# AT32F403A register map
Vendor: Keil; Series: AT32F403A; File version: 1.0
CPU: CM4 r0p1, little endian, no MPU, FPU, 4 interrupt priority bits
Registers are 32-bit, read-write, reset 0x0 unless marked. A register's access mark holds for its fields unless they carry their own. Offsets are from the block's base; [hi:lo] are bit positions; lines under a group give offsets from that group; {n}, {i} and the like mark numbered series.

## DMA1 — DMA controller
Base 0x40020000
Same registers: DMA2 0x40020400
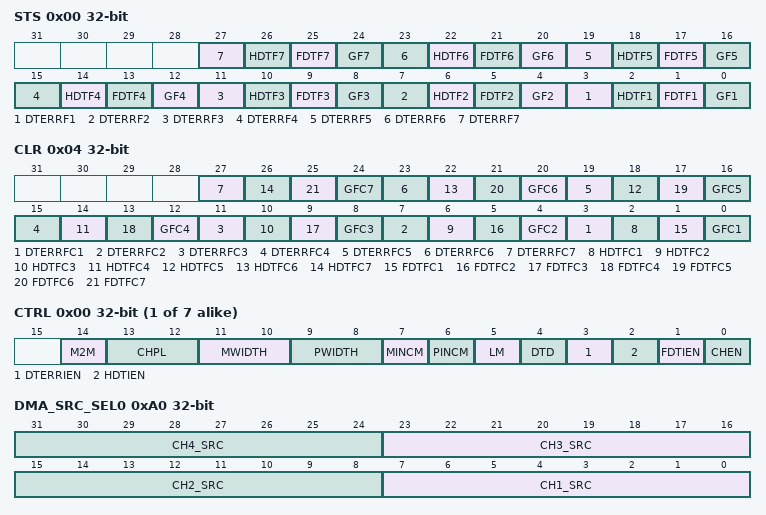
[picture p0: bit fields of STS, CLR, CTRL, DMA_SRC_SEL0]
0x00 STS ro — DMA interrupt status register (DMA_STS)
  [4n-1] DTERRF{n} (n=1..7) — Channel {n} data transfer error event flag
    0=NoTransferError; 1=TransferError (A transfer error occurred)
  [4n-2] HDTF{n} (n=1..7) — Channel {n} half transfer event flag
    0=NoHalfTransfer; 1=HalfTransfer (A half transfer occurred)
  [4n-3] FDTF{n} (n=1..7) — Channel {n} data transfer complete event flag
    0=NoTransferComplete; 1=TransferComplete (A transfer complete occurred)
  [4n-4] GF{n} (n=1..7) — Channel {n} global event flag
    0=NoEvent; 1=Event (An event occurred (transfer error, half transfer or transfer complete))
0x04 CLR — DMA interrupt flag clear register (DMA_CLR)
  [4n-1] DTERRFC{n} (n=1..7) write-1-clears — Channel {n} data transfer error flag clear
    1=Clear the transfer error flag
  [4n-2] HDTFC{n} (n=1..7) write-1-clears — Channel {n} half transfer flag clear
    1=Clear the half transfer flag
  [4n-3] FDTFC{n} (n=1..7) write-1-clears — Channel {n} data transfer complete flag clear
    1=Clear the transfer complete flag
  [4n-4] GFC{n} (n=1..7) write-1-clears — Channel {n} global flag clear
    1=Clear all flags DTERRFx, HDTFx, FDTFx and GFx
0x08 Channel{i} (i=1..7; step 0x14) group — DMA Channel {i}
  0x00 CTRL — DMA channel configuration register
    [14] M2M — Memory to memory mode
      on read: 0=Disabled (Memory to memory mode is disabled); 1=Enabled (Memory to memory mode is enabled) | on write: 0=Disable (Memory to memory mode disable); 1=Enable (Memory to memory mode enable)
    [13:12] CHPL — Channel Priority level
      0=Low; 1=Medium; 2=High; 3=VeryHigh
    [11:10] MWIDTH — Memory data bit width
      0=bit8 (8 bits); 1=bit16 (16 bits); 2=bit32 (32 bits)
    [9:8] PWIDTH — Peripheral data bit width
      0=bit8 (8 bits); 1=bit16 (16 bits); 2=bit32 (32 bits)
    [7] MINCM — Memory address increment mode
      on read: 0=Disabled (Memory address increment is disabled); 1=Enabled (Memory address increment is enabled) | on write: 0=Disable (Memory address increment disable); 1=Enable (Memory address increment enable)
    [6] PINCM — Peripheral address increment mode
      on read: 0=Disabled (Peripheral address increment is disabled); 1=Enabled (Peripheral address increment is enabled) | on write: 0=Disable (Peripheral address increment disable); 1=Enable (Peripheral address increment enable)
    [5] LM — Loop mode
      on read: 0=Disabled (Circular mode is disabled); 1=Enabled (Circular mode is enabled) | on write: 0=Disable (Circular mode disable); 1=Enable (Circular mode enable)
    [4] DTD — Data transfer direction
      0=Peripherals (Read from peripherals); 1=Memory (Read from memory)
    [3] DTERRIEN — Data transfer error interrupt enable
      on read: 0=Disabled (Data transfer error interrupt is disabled); 1=Enabled (Data transfer error interrupt is enabled) | on write: 0=Disable (Data transfer error interrupt disable); 1=Enable (Data transfer error interrupt enable)
    [2] HDTIEN — Half data transfer interrupt enable
      on read: 0=Disabled (Half-transfer interrupt is disabled); 1=Enabled (Half-transfer interrupt is enabled) | on write: 0=Disable (Half-transfer interrupt disable); 1=Enable (Half-transfer interrupt enable)
    [1] FDTIEN — Full data transfer interrupt enable
      on read: 0=Disabled (Transfer complete interrupt is disabled); 1=Enabled (Transfer complete interrupt is enabled) | on write: 0=Disable (Transfer complete interrupt disable); 1=Enable (Transfer complete interrupt enable)
    [0] CHEN — Channel enable
      on read: 0=Disabled (Channel is disabled); 1=Enabled (Channel is enabled) | on write: 0=Disable (Channel disable); 1=Enable (Channel enable)
  0x04 DTCNT — DMA channel number of data to transfer register
    [15:0] CNT — Number of data to transfer
  0x08 PADDR — DMA channel peripheral base address register
  0x0C MADDR — DMA channel memory base address register
0xA0 DMA_SRC_SEL0 — DMA channel source assignment register
  [8n-1:8n-8] CH{n}_SRC (n=1..4) — CH{n} SRC select
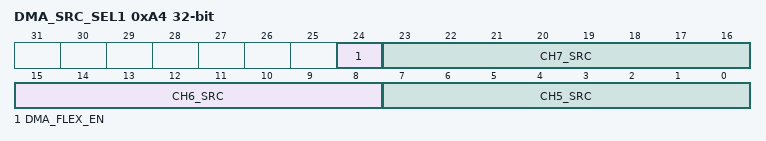
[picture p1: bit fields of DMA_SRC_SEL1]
0xA4 DMA_SRC_SEL1 — DMA channel source assignment register
  [24] DMA_FLEX_EN — DMA FLEX Enable
  [23:16] CH7_SRC — CH7 SRC select
  [15:8] CH6_SRC — CH6 SRC select
  [7:0] CH5_SRC — CH5 SRC select
